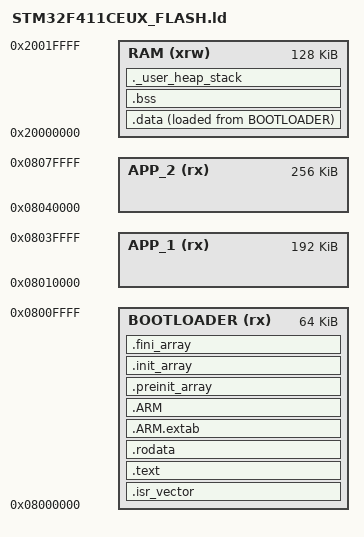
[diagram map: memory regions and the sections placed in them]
/*
******************************************************************************
**
** @file        : LinkerScript.ld
**
** @author      : Auto-generated by STM32CubeIDE
**
** @brief       : Linker script for STM32F411CEUx Device from STM32F4 series
**                      512Kbytes FLASH
**                      128Kbytes RAM
**
**                Set heap size, stack size and stack location according
**                to application requirements.
**
**                Set memory bank area and size if external memory is used
**
**  Target      : STMicroelectronics STM32
**
**  Distribution: The file is distributed as is, without any warranty
**                of any kind.
**
******************************************************************************
** @attention
**
** Copyright (c) 2025 STMicroelectronics.
** All rights reserved.
**
** This software is licensed under terms that can be found in the LICENSE file
** in the root directory of this software component.
** If no LICENSE file comes with this software, it is provided AS-IS.
**
******************************************************************************
*/

/* Entry Point */
ENTRY(Reset_Handler)

/* Highest address of the user mode stack */
_estack = ORIGIN(RAM) + LENGTH(RAM); /* end of "RAM" Ram type memory */

_Min_Heap_Size = 0x200; /* required amount of heap */
_Min_Stack_Size = 0x400; /* required amount of stack */

/* Memories definition */
MEMORY
{
  BOOTLOADER (rx) : ORIGIN = 0x08000000, LENGTH = 64K     /* Bootloader: 0x08000000 - 0x0800FFFF */
  APP_1      (rx) : ORIGIN = 0x08010000, LENGTH = 192K    /* App 1:      0x08010000 - 0x0803FFFF */
  APP_2      (rx) : ORIGIN = 0x08040000, LENGTH = 256K    /* App 2:      0x08040000 - 0x0807FFFF */
  RAM        (xrw): ORIGIN = 0x20000000, LENGTH = 128K
}

/* Symbols for bootloader to access */
PROVIDE(APP_1_START = ORIGIN(APP_1));
PROVIDE(APP_2_START = ORIGIN(APP_2));
PROVIDE(APP_1_SIZE  = LENGTH(APP_1));
PROVIDE(APP_2_SIZE  = LENGTH(APP_2));

/* Sections */
SECTIONS
{
  /* The startup code into "BOOTLOADER" Rom type memory */
  .isr_vector :
  {
    . = ALIGN(4);
    KEEP(*(.isr_vector)) /* Startup code */
    . = ALIGN(4);
  } >BOOTLOADER

  /* The program code and other data into "BOOTLOADER" Rom type memory */
  .text :
  {
    . = ALIGN(4);
    *(.text)           /* .text sections (code) */
    *(.text*)          /* .text* sections (code) */
    *(.glue_7)         /* glue arm to thumb code */
    *(.glue_7t)        /* glue thumb to arm code */
    *(.eh_frame)

    KEEP (*(.init))
    KEEP (*(.fini))

    . = ALIGN(4);
    _etext = .;        /* define a global symbols at end of code */
  } >BOOTLOADER

  /* Constant data into "BOOTLOADER" Rom type memory */
  .rodata :
  {
    . = ALIGN(4);
    *(.rodata)         /* .rodata sections (constants, strings, etc.) */
    *(.rodata*)        /* .rodata* sections (constants, strings, etc.) */
    . = ALIGN(4);
  } >BOOTLOADER

  .ARM.extab   : {
    . = ALIGN(4);
    *(.ARM.extab* .gnu.linkonce.armextab.*)
    . = ALIGN(4);
  } >BOOTLOADER

  .ARM : {
    . = ALIGN(4);
    __exidx_start = .;
    *(.ARM.exidx*)
    __exidx_end = .;
    . = ALIGN(4);
  } >BOOTLOADER

  .preinit_array     :
  {
    . = ALIGN(4);
    PROVIDE_HIDDEN (__preinit_array_start = .);
    KEEP (*(.preinit_array*))
    PROVIDE_HIDDEN (__preinit_array_end = .);
    . = ALIGN(4);
  } >BOOTLOADER

  .init_array :
  {
    . = ALIGN(4);
    PROVIDE_HIDDEN (__init_array_start = .);
    KEEP (*(SORT(.init_array.*)))
    KEEP (*(.init_array*))
    PROVIDE_HIDDEN (__init_array_end = .);
    . = ALIGN(4);
  } >BOOTLOADER

  .fini_array :
  {
    . = ALIGN(4);
    PROVIDE_HIDDEN (__fini_array_start = .);
    KEEP (*(SORT(.fini_array.*)))
    KEEP (*(.fini_array*))
    PROVIDE_HIDDEN (__fini_array_end = .);
    . = ALIGN(4);
  } >BOOTLOADER

  /* Used by the startup to initialize data */
  _sidata = LOADADDR(.data);

  /* Initialized data sections into "RAM" Ram type memory */
  .data :
  {
    . = ALIGN(4);
    _sdata = .;        /* create a global symbol at data start */
    *(.data)           /* .data sections */
    *(.data*)          /* .data* sections */
    *(.RamFunc)        /* .RamFunc sections */
    *(.RamFunc*)       /* .RamFunc* sections */

    . = ALIGN(4);
    _edata = .;        /* define a global symbol at data end */

  } >RAM AT> BOOTLOADER

  /* Uninitialized data section into "RAM" Ram type memory */
  . = ALIGN(4);
  .bss :
  {
    /* This is used by the startup in order to initialize the .bss section */
    _sbss = .;         /* define a global symbol at bss start */
    __bss_start__ = _sbss;
    *(.bss)
    *(.bss*)
    *(COMMON)

    . = ALIGN(4);
    _ebss = .;         /* define a global symbol at bss end */
    __bss_end__ = _ebss;
  } >RAM

  /* User_heap_stack section, used to check that there is enough "RAM" Ram  type memory left */
  ._user_heap_stack :
  {
    . = ALIGN(8);
    PROVIDE ( end = . );
    PROVIDE ( _end = . );
    . = . + _Min_Heap_Size;
    . = . + _Min_Stack_Size;
    . = ALIGN(8);
  } >RAM

  /* Remove information from the compiler libraries */
  /DISCARD/ :
  {
    libc.a ( * )
    libm.a ( * )
    libgcc.a ( * )
  }

  .ARM.attributes 0 : { *(.ARM.attributes) }
}
